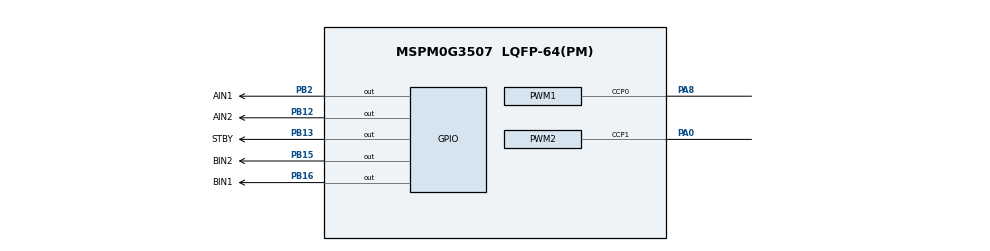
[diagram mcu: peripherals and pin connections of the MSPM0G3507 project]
/**
 * These arguments were used when this file was generated. They will be automatically applied on subsequent loads
 * via the GUI or CLI. Run CLI with '--help' for additional information on how to override these arguments.
 * @cliArgs --device "MSPM0G350X" --part "Default" --package "LQFP-64(PM)" --product "mspm0_sdk@2.11.00.07"
 * @v2CliArgs --device "MSPM0G3507" --package "LQFP-64(PM)" --product "mspm0_sdk@2.11.00.07"
 * @versions {"tool":"1.26.2+4477"}
 */

/**
 * Import the modules used in this configuration.
 */
const GPIO   = scripting.addModule("/ti/driverlib/GPIO", {}, false);
const GPIO1  = GPIO.addInstance();
const PWM    = scripting.addModule("/ti/driverlib/PWM", {}, false);
const PWM1   = PWM.addInstance();
const PWM2   = PWM.addInstance();
const SYSCTL = scripting.addModule("/ti/driverlib/SYSCTL");

/**
 * Write custom configuration values to the imported modules.
 */
const divider9       = system.clockTree["UDIV"];
divider9.divideValue = 2;

const multiplier2         = system.clockTree["PLL_QDIV"];
multiplier2.multiplyValue = 4;

const mux4       = system.clockTree["EXHFMUX"];
mux4.inputSelect = "EXHFMUX_XTAL";

const mux5       = system.clockTree["EXLFMUX"];
mux5.inputSelect = "EXLFMUX_XTAL";

const mux8       = system.clockTree["HSCLKMUX"];
mux8.inputSelect = "HSCLKMUX_SYSPLL0";

const mux12       = system.clockTree["SYSPLLMUX"];
mux12.inputSelect = "zSYSPLLMUX_HFCLK";

const pinFunction4     = system.clockTree["HFXT"];
pinFunction4.inputFreq = 40;
pinFunction4.enable    = true;

GPIO1.$name                         = "MOTOR";
GPIO1.associatedPins.create(5);
GPIO1.associatedPins[0].ioStructure = "SD";
GPIO1.associatedPins[0].$name       = "BIN1";
GPIO1.associatedPins[0].pin.$assign = "PB16";
GPIO1.associatedPins[1].$name       = "BIN2";
GPIO1.associatedPins[1].ioStructure = "SD";
GPIO1.associatedPins[1].pin.$assign = "PB15";
GPIO1.associatedPins[2].$name       = "AIN1";
GPIO1.associatedPins[2].ioStructure = "SD";
GPIO1.associatedPins[2].pin.$assign = "PB2";
GPIO1.associatedPins[3].$name       = "AIN2";
GPIO1.associatedPins[3].ioStructure = "SD";
GPIO1.associatedPins[3].pin.$assign = "PB12";
GPIO1.associatedPins[4].$name       = "STBY";
GPIO1.associatedPins[4].ioStructure = "SD";
GPIO1.associatedPins[4].pin.$assign = "PB13";

const Board = scripting.addModule("/ti/driverlib/Board", {}, false);

PWM1.$name                      = "PWMB";
PWM1.pwmMode                    = "EDGE_ALIGN_UP";
PWM1.timerStartTimer            = true;
PWM1.timerCount                 = 4000;
PWM1.clockDivider               = 2;
PWM1.ccIndex                    = [0];
PWM1.PWM_CHANNEL_0.$name        = "ti_driverlib_pwm_PWMTimerCC0";
PWM1.ccp0PinConfig.$name        = "ti_driverlib_gpio_GPIOPinGeneric1";
PWM1.peripheral.$assign         = "TIMA0";
PWM1.peripheral.ccp0Pin.$assign = "PA8";

PWM2.$name                              = "PWMA";
PWM2.timerCount                         = 4000;
PWM2.pwmMode                            = "EDGE_ALIGN_UP";
PWM2.ccIndex                            = [1];
PWM2.timerStartTimer                    = true;
PWM2.ccp1PinConfig.direction            = scripting.forceWrite("OUTPUT");
PWM2.ccp1PinConfig.hideOutputInversion  = scripting.forceWrite(false);
PWM2.ccp1PinConfig.onlyInternalResistor = scripting.forceWrite(false);
PWM2.ccp1PinConfig.passedPeripheralType = scripting.forceWrite("Digital");
PWM2.ccp1PinConfig.$name                = "ti_driverlib_gpio_GPIOPinGeneric2";
PWM2.peripheral.$assign                 = "TIMG8";
PWM2.peripheral.ccp1Pin.$assign         = "PA0";
PWM2.PWM_CHANNEL_1.$name                = "ti_driverlib_pwm_PWMTimerCC1";

SYSCTL.forceDefaultClkConfig = true;
SYSCTL.clockTreeEn           = true;

/**
 * Pinmux solution for unlocked pins/peripherals. This ensures that minor changes to the automatic solver in a future
 * version of the tool will not impact the pinmux you originally saw.  These lines can be completely deleted in order to
 * re-solve from scratch.
 */
pinFunction4.peripheral.$suggestSolution           = "SYSCTL";
pinFunction4.peripheral.hfxInPin.$suggestSolution  = "PA5";
pinFunction4.peripheral.hfxOutPin.$suggestSolution = "PA6";
Board.peripheral.$suggestSolution                  = "DEBUGSS";
Board.peripheral.swclkPin.$suggestSolution         = "PA20";
Board.peripheral.swdioPin.$suggestSolution         = "PA19";
